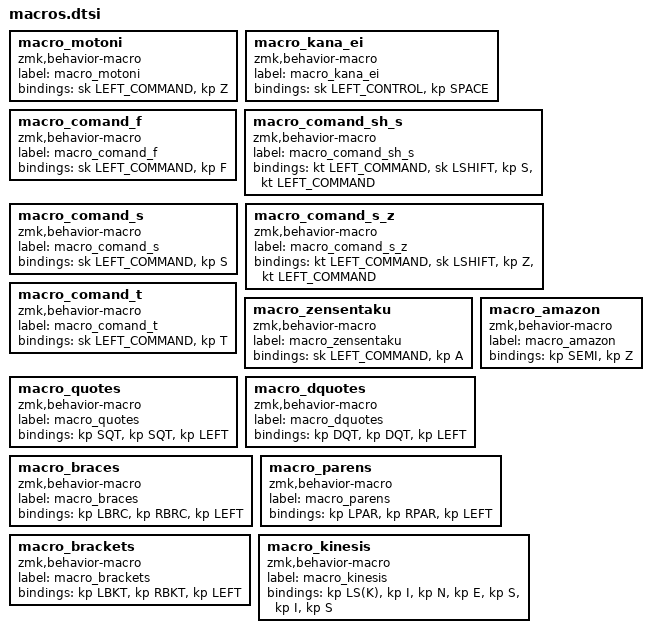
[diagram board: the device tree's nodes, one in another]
macro_motoni: macro_motoni{
compatible = "zmk,behavior-macro";
label = "macro_motoni";
#binding-cells = <0>;
bindings = <&sk LEFT_COMMAND>, <&kp Z>;
};
macro_kana_ei: macro_kana_ei{
compatible = "zmk,behavior-macro";
label = "macro_kana_ei";
#binding-cells = <0>;
bindings = <&sk LEFT_CONTROL>, <&kp SPACE>;
};
macro_comand_f: macro_comand_f{
compatible = "zmk,behavior-macro";
label = "macro_comand_f";
#binding-cells = <0>;
bindings = <&sk LEFT_COMMAND>, <&kp F>;
};
macro_comand_sh_s: macro_comand_sh_s{
compatible = "zmk,behavior-macro";
label = "macro_comand_sh_s";
#binding-cells = <0>;
bindings = <&kt LEFT_COMMAND>, <&sk LSHIFT>, <&kp S>, <&kt LEFT_COMMAND>;
};
macro_comand_s: macro_comand_s{
compatible = "zmk,behavior-macro";
label = "macro_comand_s";
#binding-cells = <0>;
bindings = <&sk LEFT_COMMAND>, <&kp S>;
};
macro_comand_s_z: macro_comand_s_z{
compatible = "zmk,behavior-macro";
label = "macro_comand_s_z";
#binding-cells = <0>;
bindings = <&kt LEFT_COMMAND>, <&sk LSHIFT>, <&kp Z>, <&kt LEFT_COMMAND>;
};
macro_comand_t: macro_comand_t{
compatible = "zmk,behavior-macro";
label = "macro_comand_t";
#binding-cells = <0>;
bindings = <&sk LEFT_COMMAND>, <&kp T>;
};
macro_zensentaku: macro_zensentaku{
compatible = "zmk,behavior-macro";
label = "macro_zensentaku";
#binding-cells = <0>;
bindings = <&sk LEFT_COMMAND>, <&kp A>;
};
macro_amazon: macro_amazon{
compatible = "zmk,behavior-macro";
label = "macro_amazon";
#binding-cells = <0>;
bindings = <&kp SEMI>, <&kp Z>;
};
macro_quotes: macro_quotes{
compatible = "zmk,behavior-macro";
label = "macro_quotes";
#binding-cells = <0>;
bindings = <&kp SQT>, <&kp SQT>, <&kp LEFT>;
};
macro_dquotes: macro_dquotes{
compatible = "zmk,behavior-macro";
label = "macro_dquotes";
#binding-cells = <0>;
bindings = <&kp DQT>, <&kp DQT>, <&kp LEFT>;
};
macro_braces: macro_braces{
compatible = "zmk,behavior-macro";
label = "macro_braces";
#binding-cells = <0>;
bindings = <&kp LBRC>, <&kp RBRC>, <&kp LEFT>;
};
macro_parens: macro_parens{
compatible = "zmk,behavior-macro";
label = "macro_parens";
#binding-cells = <0>;
bindings = <&kp LPAR>, <&kp RPAR>, <&kp LEFT>;
};
macro_brackets: macro_brackets{
compatible = "zmk,behavior-macro";
label = "macro_brackets";
#binding-cells = <0>;
bindings = <&kp LBKT>, <&kp RBKT>, <&kp LEFT>;
};
macro_kinesis: macro_kinesis{
compatible = "zmk,behavior-macro";
label = "macro_kinesis";
#binding-cells = <0>;
bindings = <&kp LS(K)>, <&kp I>, <&kp N>, <&kp E>, <&kp S>, <&kp I>, <&kp S>;
};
